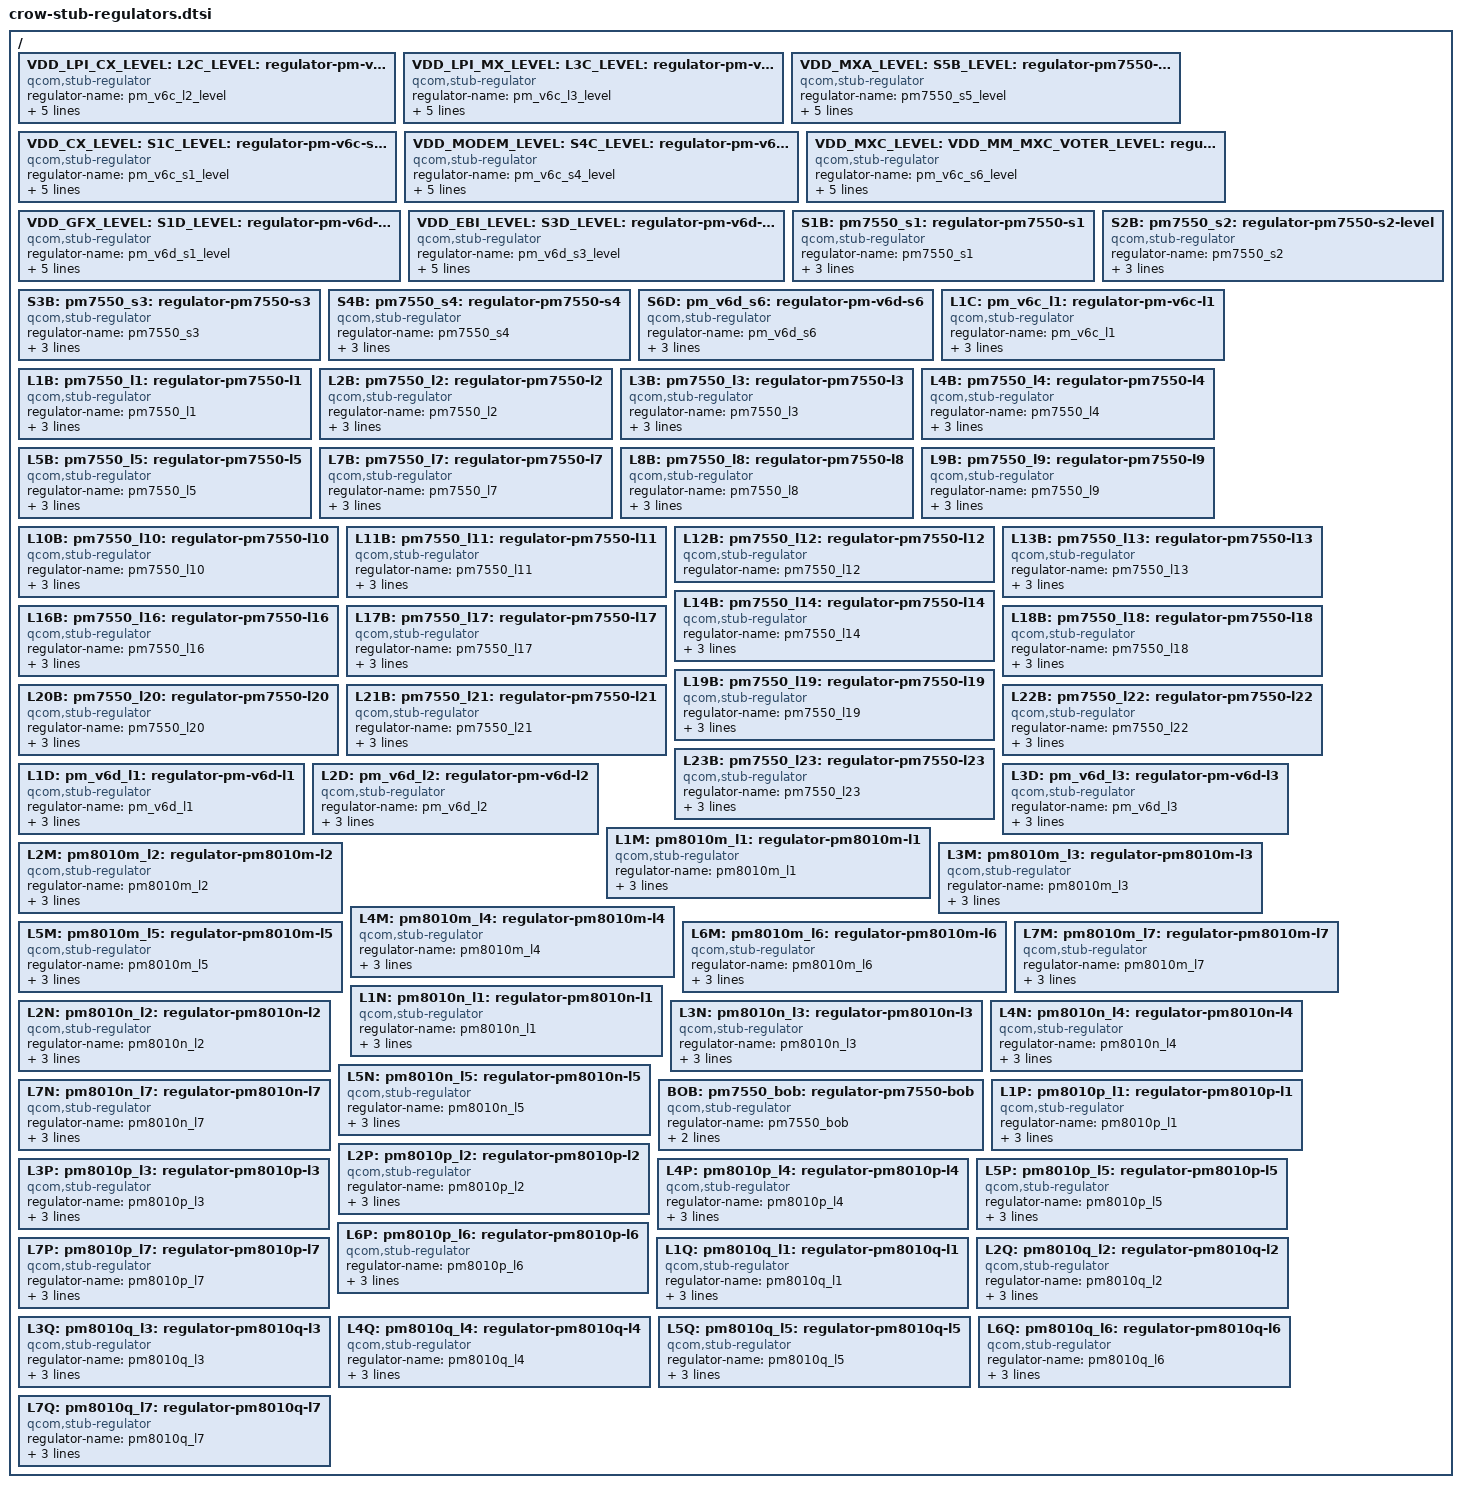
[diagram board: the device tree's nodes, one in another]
#include <dt-bindings/regulator/qcom,rpmh-regulator-levels.h>

/ {
	VDD_LPI_CX_LEVEL:
	L2C_LEVEL:
	pm_v6c_l2_level: regulator-pm-v6c-l2_level {
		compatible = "qcom,stub-regulator";
		regulator-name = "pm_v6c_l2_level";
		qcom,hpm-min-load = <30000>;
		regulator-min-microvolt = <RPMH_REGULATOR_LEVEL_RETENTION>;
		regulator-max-microvolt = <RPMH_REGULATOR_LEVEL_MAX>;
	};

	VDD_LPI_MX_LEVEL:
	L3C_LEVEL:
	pm_v6c_l3_level: regulator-pm-v6c-l3-level {
		compatible = "qcom,stub-regulator";
		regulator-name = "pm_v6c_l3_level";
		qcom,hpm-min-load = <30000>;
		regulator-min-microvolt = <RPMH_REGULATOR_LEVEL_RETENTION>;
		regulator-max-microvolt = <RPMH_REGULATOR_LEVEL_MAX>;
	};

	VDD_MXA_LEVEL:
	S5B_LEVEL:
	pm7550_s5_level: regulator-pm7550-s5-level {
		compatible = "qcom,stub-regulator";
		regulator-name = "pm7550_s5_level";
		regulator-min-microvolt = <RPMH_REGULATOR_LEVEL_RETENTION>;
		regulator-max-microvolt = <RPMH_REGULATOR_LEVEL_MAX>;
		qcom,hpm-min-load = <10000>;
	};

	VDD_CX_LEVEL:
	S1C_LEVEL:
	pm_v6c_s1_level: regulator-pm-v6c-s1-level {
		compatible = "qcom,stub-regulator";
		regulator-name = "pm_v6c_s1_level";
		qcom,hpm-min-load = <10000>;
		regulator-min-microvolt = <RPMH_REGULATOR_LEVEL_RETENTION>;
		regulator-max-microvolt = <RPMH_REGULATOR_LEVEL_MAX>;
	};

	VDD_MODEM_LEVEL:
	S4C_LEVEL:
	pm_v6c_s4_level: regulator-pm-v6c-s4-level {
		compatible = "qcom,stub-regulator";
		regulator-name = "pm_v6c_s4_level";
		qcom,hpm-min-load = <10000>;
		regulator-min-microvolt = <RPMH_REGULATOR_LEVEL_RETENTION>;
		regulator-max-microvolt = <RPMH_REGULATOR_LEVEL_MAX>;
	};

	VDD_MXC_LEVEL:
	VDD_MM_MXC_VOTER_LEVEL:
	VDD_GFX_MXC_VOTER_LEVEL:
	S6C_LEVEL:
	pm_v6c_s6_level: regulator-pm-v6c-s6-level {
		compatible = "qcom,stub-regulator";
		regulator-name = "pm_v6c_s6_level";
		qcom,hpm-min-load = <10000>;
		regulator-min-microvolt = <RPMH_REGULATOR_LEVEL_RETENTION>;
		regulator-max-microvolt = <RPMH_REGULATOR_LEVEL_MAX>;
	};

	VDD_GFX_LEVEL:
	S1D_LEVEL:
	pm_v6d_s1_level: regulator-pm-v6d-s1-level {
		compatible = "qcom,stub-regulator";
		regulator-name = "pm_v6d_s1_level";
		qcom,hpm-min-load = <30000>;
		regulator-min-microvolt = <RPMH_REGULATOR_LEVEL_RETENTION>;
		regulator-max-microvolt = <RPMH_REGULATOR_LEVEL_MAX>;
	};

	VDD_EBI_LEVEL:
	S3D_LEVEL:
	pm_v6d_s3_level: regulator-pm-v6d-s3-level {
		compatible = "qcom,stub-regulator";
		regulator-name = "pm_v6d_s3_level";
		qcom,hpm-min-load = <10000>;
		regulator-min-microvolt = <RPMH_REGULATOR_LEVEL_RETENTION>;
		regulator-max-microvolt = <RPMH_REGULATOR_LEVEL_MAX>;
	};

	S1B: pm7550_s1: regulator-pm7550-s1 {
		compatible = "qcom,stub-regulator";
		regulator-name = "pm7550_s1";
		regulator-min-microvolt = <1856000>;
		regulator-max-microvolt = <2040000>;
		qcom,hpm-min-load = <10000>;
	};

	S2B: pm7550_s2: regulator-pm7550-s2-level {
		compatible = "qcom,stub-regulator";
		regulator-name = "pm7550_s2";
		regulator-min-microvolt = <1256000>;
		regulator-max-microvolt = <2050000>;
		qcom,hpm-min-load = <10000>;
	};

	S3B: pm7550_s3: regulator-pm7550-s3 {
		compatible = "qcom,stub-regulator";
		regulator-name = "pm7550_s3";
		regulator-min-microvolt = <880000>;
		regulator-max-microvolt = <1040000>;
		qcom,hpm-min-load = <10000>;
	};

	S4B: pm7550_s4: regulator-pm7550-s4 {
		compatible = "qcom,stub-regulator";
		regulator-name = "pm7550_s4";
		regulator-min-microvolt = <2200000>;
		regulator-max-microvolt = <2200000>;
		qcom,hpm-min-load = <10000>;
	};

	S6D: pm_v6d_s6: regulator-pm-v6d-s6 {
		compatible = "qcom,stub-regulator";
		regulator-name = "pm_v6d_s6";
		qcom,hpm-min-load = <10000>;
		regulator-min-microvolt = <1010000>;
		regulator-max-microvolt = <1170000>;
	};

	L1C: pm_v6c_l1: regulator-pm-v6c-l1 {
		compatible = "qcom,stub-regulator";
		regulator-name = "pm_v6c_l1";
		qcom,hpm-min-load = <10000>;
		regulator-min-microvolt = <300000>;
		regulator-max-microvolt = <650000>;
	};

	L1B: pm7550_l1: regulator-pm7550-l1 {
		compatible = "qcom,stub-regulator";
		regulator-name = "pm7550_l1";
		regulator-min-microvolt = <880000>;
		regulator-max-microvolt = <912000>;
		qcom,hpm-min-load = <10000>;
	};

	L2B: pm7550_l2: regulator-pm7550-l2 {
		compatible = "qcom,stub-regulator";
		regulator-name = "pm7550_l2";
		regulator-min-microvolt = <880000>;
		regulator-max-microvolt = <912000>;
		qcom,hpm-min-load = <10000>;
	};

	L3B: pm7550_l3: regulator-pm7550-l3 {
		compatible = "qcom,stub-regulator";
		regulator-name = "pm7550_l3";
		regulator-min-microvolt = <880000>;
		regulator-max-microvolt = <912000>;
		qcom,hpm-min-load = <10000>;
	};

	L4B: pm7550_l4: regulator-pm7550-l4 {
		compatible = "qcom,stub-regulator";
		regulator-name = "pm7550_l4";
		regulator-min-microvolt = <1200000>;
		regulator-max-microvolt = <1200000>;
		qcom,hpm-min-load = <10000>;
	};

	L5B: pm7550_l5: regulator-pm7550-l5 {
		compatible = "qcom,stub-regulator";
		regulator-name = "pm7550_l5";
		regulator-min-microvolt = <1200000>;
		regulator-max-microvolt = <1200000>;
		qcom,hpm-min-load = <10000>;
	};

	L7B: pm7550_l7: regulator-pm7550-l7 {
		compatible = "qcom,stub-regulator";
		regulator-name = "pm7550_l7";
		regulator-min-microvolt = <1800000>;
		regulator-max-microvolt = <1800000>;
		qcom,hpm-min-load = <10000>;
	};

	L8B: pm7550_l8: regulator-pm7550-l8 {
		compatible = "qcom,stub-regulator";
		regulator-name = "pm7550_l8";
		regulator-min-microvolt = <1800000>;
		regulator-max-microvolt = <1800000>;
		qcom,hpm-min-load = <10000>;
	};

	L9B: pm7550_l9: regulator-pm7550-l9 {
		compatible = "qcom,stub-regulator";
		regulator-name = "pm7550_l9";
		regulator-min-microvolt = <1800000>;
		regulator-max-microvolt = <1800000>;
		qcom,hpm-min-load = <10000>;
	};

	L10B: pm7550_l10: regulator-pm7550-l10 {
		compatible = "qcom,stub-regulator";
		regulator-name = "pm7550_l10";
		regulator-min-microvolt = <1800000>;
		regulator-max-microvolt = <1800000>;
		qcom,hpm-min-load = <10000>;
	};

	L11B: pm7550_l11: regulator-pm7550-l11 {
		compatible = "qcom,stub-regulator";
		regulator-name = "pm7550_l11";
		regulator-min-microvolt = <1800000>;
		regulator-max-microvolt = <1800000>;
		qcom,hpm-min-load = <10000>;
	};

	L12B: pm7550_l12: regulator-pm7550-l12 {
		compatible = "qcom,stub-regulator";
		regulator-name = "pm7550_l12";

	/*
	 * Removed min/max and init for UFS_VCC,
	 * as voltage set from the BOOT should not
	 * be changed
	 */

	};

	L13B: pm7550_l13: regulator-pm7550-l13 {
		compatible = "qcom,stub-regulator";
		regulator-name = "pm7550_l13";
		regulator-min-microvolt = <2700000>;
		regulator-max-microvolt = <3300000>;
		qcom,hpm-min-load = <10000>;
	};

	L14B: pm7550_l14: regulator-pm7550-l14 {
		compatible = "qcom,stub-regulator";
		regulator-name = "pm7550_l14";
		regulator-min-microvolt = <2650000>;
		regulator-max-microvolt = <2950000>;
		qcom,hpm-min-load = <10000>;
	};

	L16B: pm7550_l16: regulator-pm7550-l16 {
		compatible = "qcom,stub-regulator";
		regulator-name = "pm7550_l16";
		regulator-min-microvolt = <3008000>;
		regulator-max-microvolt = <3008000>;
		qcom,hpm-min-load = <10000>;
	};

	L17B: pm7550_l17: regulator-pm7550-l17 {
		compatible = "qcom,stub-regulator";
		regulator-name = "pm7550_l17";
		regulator-min-microvolt = <3104000>;
		regulator-max-microvolt = <3104000>;
		qcom,hpm-min-load = <10000>;
	};

	L18B: pm7550_l18: regulator-pm7550-l18 {
		compatible = "qcom,stub-regulator";
		regulator-name = "pm7550_l18";
		regulator-min-microvolt = <2800000>;
		regulator-max-microvolt = <2800000>;
		qcom,hpm-min-load = <10000>;
	};

	L19B: pm7550_l19: regulator-pm7550-l19 {
		compatible = "qcom,stub-regulator";
		regulator-name = "pm7550_l19";
		regulator-min-microvolt = <3000000>;
		regulator-max-microvolt = <3000000>;
		qcom,hpm-min-load = <10000>;
	};

	L20B: pm7550_l20: regulator-pm7550-l20 {
		compatible = "qcom,stub-regulator";
		regulator-name = "pm7550_l20";
		regulator-min-microvolt = <1620000>;
		regulator-max-microvolt = <3544000>;
		qcom,hpm-min-load = <10000>;
	};

	L21B: pm7550_l21: regulator-pm7550-l21 {
		compatible = "qcom,stub-regulator";
		regulator-name = "pm7550_l21";
		regulator-min-microvolt = <1620000>;
		regulator-max-microvolt = <3544000>;
		qcom,hpm-min-load = <10000>;
	};

	L22B: pm7550_l22: regulator-pm7550-l22 {
		compatible = "qcom,stub-regulator";
		regulator-name = "pm7550_l22";
		regulator-min-microvolt = <3200000>;
		regulator-max-microvolt = <3200000>;
		qcom,hpm-min-load = <10000>;
	};

	L23B: pm7550_l23: regulator-pm7550-l23 {
		compatible = "qcom,stub-regulator";
		regulator-name = "pm7550_l23";
		regulator-min-microvolt = <1650000>;
		regulator-max-microvolt = <3544000>;
		qcom,hpm-min-load = <10000>;
	};

	L1D:
	pm_v6d_l1: regulator-pm-v6d-l1 {
		compatible = "qcom,stub-regulator";
		regulator-name = "pm_v6d_l1";
		regulator-min-microvolt = <870000>;
		regulator-max-microvolt = <970000>;
		qcom,hpm-min-load = <30000>;
	};

	L2D:
	pm_v6d_l2: regulator-pm-v6d-l2 {
		compatible = "qcom,stub-regulator";
		regulator-name = "pm_v6d_l2";
		regulator-min-microvolt = <1140000>;
		regulator-max-microvolt = <1950000>;
		qcom,hpm-min-load = <30000>;
	};

	L3D:
	pm_v6d_l3: regulator-pm-v6d-l3 {
		compatible = "qcom,stub-regulator";
		regulator-name = "pm_v6d_l3";
		regulator-min-microvolt = <1200000>;
		regulator-max-microvolt = <1200000>;
		qcom,hpm-min-load = <30000>;
	};

	L1M:
	pm8010m_l1: regulator-pm8010m-l1 {
		compatible = "qcom,stub-regulator";
		regulator-name = "pm8010m_l1";
		regulator-min-microvolt = <1050000>;
		regulator-max-microvolt = <1180000>;
		qcom,hpm-min-load = <30000>;
	};

	L2M:
	pm8010m_l2: regulator-pm8010m-l2 {
		compatible = "qcom,stub-regulator";
		regulator-name = "pm8010m_l2";
		regulator-min-microvolt = <950000>;
		regulator-max-microvolt = <1150000>;
		qcom,hpm-min-load = <30000>;
	};

	L3M:
	pm8010m_l3: regulator-pm8010m-l3 {
		compatible = "qcom,stub-regulator";
		regulator-name = "pm8010m_l3";
		regulator-min-microvolt = <2700000>;
		regulator-max-microvolt = <2900000>;
		qcom,hpm-min-load = <30000>;
	};

	L4M:
	pm8010m_l4: regulator-pm8010m-l4 {
		compatible = "qcom,stub-regulator";
		regulator-name = "pm8010m_l4";
		regulator-min-microvolt = <2700000>;
		regulator-max-microvolt = <2900000>;
		qcom,hpm-min-load = <30000>;
	};

	L5M:
	pm8010m_l5: regulator-pm8010m-l5 {
		compatible = "qcom,stub-regulator";
		regulator-name = "pm8010m_l5";
		regulator-min-microvolt = <1700000>;
		regulator-max-microvolt = <1900000>;
		qcom,hpm-min-load = <30000>;
	};

	L6M:
	pm8010m_l6: regulator-pm8010m-l6 {
		compatible = "qcom,stub-regulator";
		regulator-name = "pm8010m_l6";
		regulator-min-microvolt = <2700000>;
		regulator-max-microvolt = <2900000>;
		qcom,hpm-min-load = <30000>;
	};

	L7M:
	pm8010m_l7: regulator-pm8010m-l7 {
		compatible = "qcom,stub-regulator";
		regulator-name = "pm8010m_l7";
		regulator-min-microvolt = <2700000>;
		regulator-max-microvolt = <3000000>;
		qcom,hpm-min-load = <30000>;
	};

	L1N:
	pm8010n_l1: regulator-pm8010n-l1 {
		compatible = "qcom,stub-regulator";
		regulator-name = "pm8010n_l1";
		regulator-min-microvolt = <1050000>;
		regulator-max-microvolt = <1200000>;
		qcom,hpm-min-load = <30000>;
	};

	L2N:
	pm8010n_l2: regulator-pm8010n-l2 {
		compatible = "qcom,stub-regulator";
		regulator-name = "pm8010n_l2";
		regulator-min-microvolt = <950000>;
		regulator-max-microvolt = <115000>;
		qcom,hpm-min-load = <30000>;
	};

	L3N:
	pm8010n_l3: regulator-pm8010n-l3 {
		compatible = "qcom,stub-regulator";
		regulator-name = "pm8010n_l3";
		regulator-min-microvolt = <1792000>;
		regulator-max-microvolt = <1980000>;
		qcom,hpm-min-load = <30000>;
	};

	L4N:
	pm8010n_l4: regulator-pm8010n-l4 {
		compatible = "qcom,stub-regulator";
		regulator-name = "pm8010n_l4";
		regulator-min-microvolt = <1792000>;
		regulator-max-microvolt = <1900000>;
		qcom,hpm-min-load = <30000>;
	};

	L5N:
	pm8010n_l5: regulator-pm8010n-l5 {
		compatible = "qcom,stub-regulator";
		regulator-name = "pm8010n_l5";
		regulator-min-microvolt = <2700000>;
		regulator-max-microvolt = <2900000>;
		qcom,hpm-min-load = <30000>;
	};

	L7N:
	pm8010n_l7: regulator-pm8010n-l7 {
		compatible = "qcom,stub-regulator";
		regulator-name = "pm8010n_l7";
		regulator-min-microvolt = <2500000>;
		regulator-max-microvolt = <3300000>;
		qcom,hpm-min-load = <30000>;
	};

	BOB: pm7550_bob: regulator-pm7550-bob {
		compatible = "qcom,stub-regulator";
		regulator-name = "pm7550_bob";
		regulator-min-microvolt = <3008000>;
		regulator-max-microvolt = <3960000>;
	};

	L1P:
	pm8010p_l1: regulator-pm8010p-l1 {
		compatible = "qcom,stub-regulator";
		regulator-name = "pm8010p_l1";
		regulator-min-microvolt = <1050000>;
		regulator-max-microvolt = <1180000>;
		qcom,hpm-min-load = <30000>;
	};

	L2P:
	pm8010p_l2: regulator-pm8010p-l2 {
		compatible = "qcom,stub-regulator";
		regulator-name = "pm8010p_l2";
		regulator-min-microvolt = <950000>;
		regulator-max-microvolt = <1150000>;
		qcom,hpm-min-load = <30000>;
	};

	L3P:
	pm8010p_l3: regulator-pm8010p-l3 {
		compatible = "qcom,stub-regulator";
		regulator-name = "pm8010p_l3";
		regulator-min-microvolt = <2700000>;
		regulator-max-microvolt = <2900000>;
		qcom,hpm-min-load = <30000>;
	};

	L4P:
	pm8010p_l4: regulator-pm8010p-l4 {
		compatible = "qcom,stub-regulator";
		regulator-name = "pm8010p_l4";
		regulator-min-microvolt = <2700000>;
		regulator-max-microvolt = <2900000>;
		qcom,hpm-min-load = <30000>;
	};

	L5P:
	pm8010p_l5: regulator-pm8010p-l5 {
		compatible = "qcom,stub-regulator";
		regulator-name = "pm8010p_l5";
		regulator-min-microvolt = <1700000>;
		regulator-max-microvolt = <1900000>;
		qcom,hpm-min-load = <30000>;
	};

	L6P:
	pm8010p_l6: regulator-pm8010p-l6 {
		compatible = "qcom,stub-regulator";
		regulator-name = "pm8010p_l6";
		regulator-min-microvolt = <2700000>;
		regulator-max-microvolt = <2900000>;
		qcom,hpm-min-load = <30000>;
	};

	L7P:
	pm8010p_l7: regulator-pm8010p-l7 {
		compatible = "qcom,stub-regulator";
		regulator-name = "pm8010p_l7";
		regulator-min-microvolt = <2700000>;
		regulator-max-microvolt = <3000000>;
		qcom,hpm-min-load = <30000>;
	};

	L1Q:
	pm8010q_l1: regulator-pm8010q-l1 {
		compatible = "qcom,stub-regulator";
		regulator-name = "pm8010q_l1";
		regulator-min-microvolt = <1050000>;
		regulator-max-microvolt = <1200000>;
		qcom,hpm-min-load = <30000>;
	};

	L2Q:
	pm8010q_l2: regulator-pm8010q-l2 {
		compatible = "qcom,stub-regulator";
		regulator-name = "pm8010q_l2";
		regulator-min-microvolt = <950000>;
		regulator-max-microvolt = <115000>;
		qcom,hpm-min-load = <30000>;
	};

	L3Q:
	pm8010q_l3: regulator-pm8010q-l3 {
		compatible = "qcom,stub-regulator";
		regulator-name = "pm8010q_l3";
		regulator-min-microvolt = <1620000>;
		regulator-max-microvolt = <1980000>;
		qcom,hpm-min-load = <30000>;
	};

	L4Q:
	pm8010q_l4: regulator-pm8010q-l4 {
		compatible = "qcom,stub-regulator";
		regulator-name = "pm8010q_l4";
		regulator-min-microvolt = <1700000>;
		regulator-max-microvolt = <1900000>;
		qcom,hpm-min-load = <30000>;
	};

	L5Q:
	pm8010q_l5: regulator-pm8010q-l5 {
		compatible = "qcom,stub-regulator";
		regulator-name = "pm8010q_l5";
		regulator-min-microvolt = <2700000>;
		regulator-max-microvolt = <2900000>;
		qcom,hpm-min-load = <30000>;
	};

	L6Q:
	pm8010q_l6: regulator-pm8010q-l6 {
		compatible = "qcom,stub-regulator";
		regulator-name = "pm8010q_l6";
		regulator-min-microvolt = <1504000>;
		regulator-max-microvolt = <3544000>;
		qcom,hpm-min-load = <30000>;
	};

	L7Q:
	pm8010q_l7: regulator-pm8010q-l7 {
		compatible = "qcom,stub-regulator";
		regulator-name = "pm8010q_l7";
		regulator-min-microvolt = <2500000>;
		regulator-max-microvolt = <3300000>;
		qcom,hpm-min-load = <30000>;
	};
};

